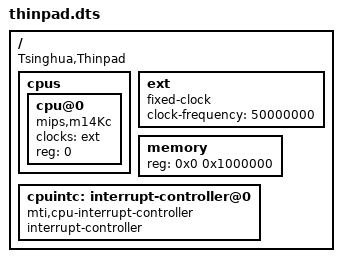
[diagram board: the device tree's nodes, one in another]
/dts-v1/;


/ {
	compatible = "Tsinghua,Thinpad";
	#address-cells = <1>;
	#size-cells = <1>;

	cpus {
		#address-cells = <1>;
		#size-cells = <0>;
		cpu@0 {
			device_type = "cpu";
			compatible = "mips,m14Kc";
			clocks	= <&ext>;
			reg = <0>;
		};
	};

	ext: ext {
		compatible = "fixed-clock";
		#clock-cells = <0>;
	};

	memory {
		device_type = "memory";
		reg = <0x0 0x1000000>;
	};

	cpuintc: interrupt-controller@0 {
		#address-cells = <0>;
		#interrupt-cells = <1>;
		interrupt-controller;
		compatible = "mti,cpu-interrupt-controller";
	};
	/*
	soc{
		compatible = "simple-bus";
		#address-cells = <1>;
		#interrupt-cells = <1>;
		ranges;
		
		serial0: serial@0x1fd003F8 {
			device_type = "serial";
			compatible = "serial8250";
			reg = <0x1fd003F8 0x100>;
			reg-shift = <2>;
			reg-io-width = <4>;
			clock-frequency = <1843200>;
			interrupt-parent = <&cpuintc>;
			interrupts = <4>;
		};

	};

	*/
};

&ext {
	clock-frequency = <50000000>;
};
